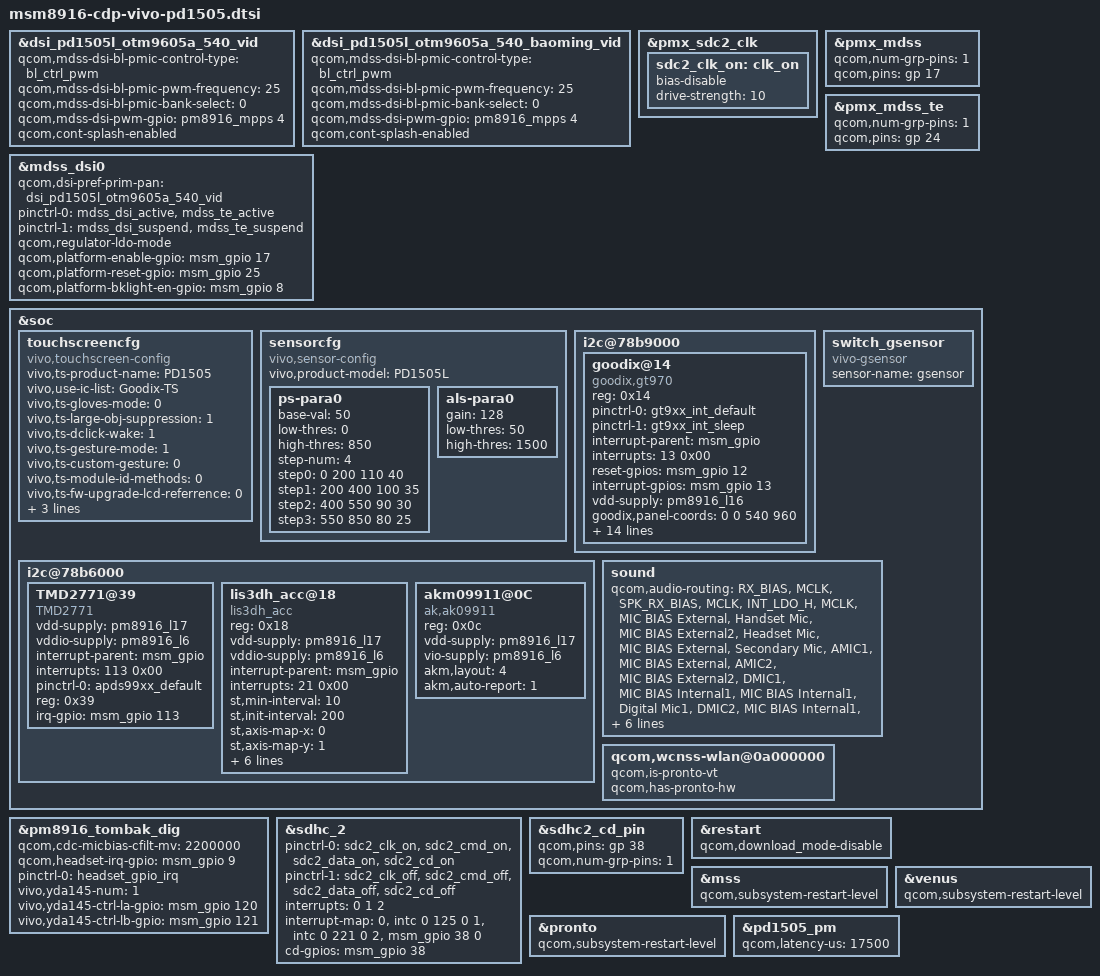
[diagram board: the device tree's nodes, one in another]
/* Copyright (c) 2014-2015, The Linux Foundation. All rights reserved.
 *
 * This program is free software; you can redistribute it and/or modify
 * it under the terms of the GNU General Public License version 2 and
 * only version 2 as published by the Free Software Foundation.
 *
 * This program is distributed in the hope that it will be useful,
 * but WITHOUT ANY WARRANTY; without even the implied warranty of
 * MERCHANTABILITY or FITNESS FOR A PARTICULAR PURPOSE.  See the
 * GNU General Public License for more details.
 */
 
#include "dsi-panel-pd1505l-otm9605a-540p-video.dtsi"
#include "dsi-panel-pd1505l-otm9605a-540p-video-baoming.dtsi"
#include "msm8916-camera-sensor-cdp-vivo-pd1505.dtsi"

 &dsi_pd1505l_otm9605a_540_vid {
	qcom,mdss-dsi-bl-pmic-control-type = "bl_ctrl_pwm";
	qcom,mdss-dsi-bl-pmic-pwm-frequency = <25>;
	qcom,mdss-dsi-bl-pmic-bank-select = <0>;
	qcom,mdss-dsi-pwm-gpio = <&pm8916_mpps 4 0>;
	qcom,cont-splash-enabled;
};

&dsi_pd1505l_otm9605a_540_baoming_vid {
	qcom,mdss-dsi-bl-pmic-control-type = "bl_ctrl_pwm";
	qcom,mdss-dsi-bl-pmic-pwm-frequency = <25>;
	qcom,mdss-dsi-bl-pmic-bank-select = <0>;
	qcom,mdss-dsi-pwm-gpio = <&pm8916_mpps 4 0>;
	qcom,cont-splash-enabled;
};


&pmx_sdc2_clk {
    sdc2_clk_on: clk_on {
        bias-disable; /* NO pull */
        drive-strength = <10>; /* 10 MA： 16 MA is too high for PD1505L */
    };
};

&pmx_mdss {
	qcom,num-grp-pins = <1>;
	qcom,pins = <&gp 17>;
};

&pmx_mdss_te {
	qcom,num-grp-pins = <1>;
	qcom,pins = <&gp 24>;
};
&mdss_dsi0 {
	qcom,dsi-pref-prim-pan = <&dsi_pd1505l_otm9605a_540_vid>;
	pinctrl-names = "mdss_default", "mdss_sleep";
	pinctrl-0 = <&mdss_dsi_active &mdss_te_active>;
	pinctrl-1 = <&mdss_dsi_suspend &mdss_te_suspend>;
	qcom,regulator-ldo-mode;
	qcom,platform-enable-gpio = <&msm_gpio 17 0>;
	qcom,platform-reset-gpio = <&msm_gpio 25 0>;
	qcom,platform-bklight-en-gpio = <&msm_gpio 8 0>;
}; 

&soc {

	touchscreencfg { /* vivo ts configure */
	   compatible = "vivo,touchscreen-config";
	   vivo,ts-product-name="PD1505";
	   vivo,use-ic-list="Goodix-TS";
	   
	   /*----- function set BEG ---- */
	   vivo,ts-gloves-mode=<0>;
	   vivo,ts-large-obj-suppression=<1>;
	   vivo,ts-dclick-wake=<1>;
	   vivo,ts-gesture-mode=<1>; /*1=sold in native,2=sold in abroad,3...etc=for custom extensive*/
	   vivo,ts-custom-gesture=<0>;
	   vivo,ts-module-id-methods=<0>;/*0=by IC id,1=gpio,2=by LCD ID 3=...etc=for custom extensive*/
	   vivo,ts-fw-upgrade-lcd-referrence=<0>;
	   vivo,ts-anti-esd=<1>;
	   vivo,ts-charger-conn-judge=<1>;
	   vivo,ts-module-smt-mode=<1>; /* 0=COB,1=COF */
	   /*----- function set END ---- */

	};
	
	sensorcfg {
		compatible = "vivo,sensor-config";
		vivo,product-model = "PD1505L";
		ps-para0 {
			base-val = <50>;
			low-thres = <0>;
			high-thres = <850>;
			step-num = <4>;
			step0 = <  0 200 110 40>;
			step1 = <200 400 100 35>;
			step2 = <400 550 90 30>;
			step3 = <550 850 80 25>;
		};
		
		als-para0 {
			gain = <128>;
			low-thres = <50>;
			high-thres = <1500>;
		};
	};

	
	i2c@78b9000 { /* BLSP1 QUP5 */
		goodix@14 { //gt970L
			compatible = "goodix,gt970";
			reg = <0x14>;
			/* pins used by touchscreen */
			pinctrl-names = "gt9xx_int_default","gt9xx_int_suspend";
            		pinctrl-0 = <&gt9xx_int_default>;
            		pinctrl-1 = <&gt9xx_int_sleep>;
			interrupt-parent = <&msm_gpio>;
			interrupts = <13 0x00>;
			reset-gpios = <&msm_gpio 12 0x00>;
			interrupt-gpios = <&msm_gpio 13 0x00>;
            		//vcc_i2c-supply = <&pm8916_l6>;
            		vdd-supply = <&pm8916_l16>;/* <&tp_power>;*/
			goodix,panel-coords = <0 0 540 960>;
			goodix,display-coords = <0 0 540 960>;
			goodix,button-map= <158 102 139>;
			goodix,family-id = <0x0>;
           		goodix,i2c-pull-up;
			goodix,cfg-data0 =    //lansi PD1505F_EX项目
			[
				 48 1C 02 09 04 0A 34 10 01 08 
				 32 08 55 32 33 35 00 00 37 13 
				 00 22 00 14 14 28 14 8B 2B 0C 
				 37 39 D3 07 D3 07 00 9A 33 11 
				 00 00 00 00 00 03 00 08 0A A0 
				 22 1E 5F 94 D0 02 BC 19 00 04 
				 C6 21 00 A0 2A 1E 84 35 00 6D 
				 43 00 5B 55 00 5B 00 00 00 00 
				 00 00 00 00 00 00 00 00 00 00 
				 00 00 00 00 F7 01 00 00 00 00 
				 00 00 00 00 00 0F 50 00 00 00 
				 00 1E 0E 10 12 18 16 14 06 04 
				 02 08 0A 0C FF FF 00 00 00 00 
				 00 00 00 00 08 00 78 04 FE 00 
				 50 41 00 02 04 06 08 0A 0C 0F 
				 10 12 13 16 18 1C 1D 1E 1F 20 
				 21 22 24 26 FF FF FF FF 00 00 
				 00 00 00 00 00 00 00 00 00 00 
				 00 00 00 00 C6 01
			];                                         
			
			goodix,cfg-data2 =    //lansi
			[
				 48 1C 02 09 04 0A 34 10 01 08 
				 32 08 55 32 33 35 00 00 37 13 
				 00 22 00 14 14 28 14 8B 2B 0C 
				 37 39 D3 07 D3 07 00 9A 33 11 
				 00 00 00 00 00 03 00 08 0A A0 
				 22 1E 5F 94 D0 02 BC 19 00 04 
				 C6 21 00 A0 2A 1E 84 35 00 6D 
				 43 00 5B 55 00 5B 00 00 00 00 
				 00 00 00 00 00 00 00 00 00 00 
				 00 00 00 00 F7 01 00 00 00 00 
				 00 00 00 00 00 0F 50 00 00 00 
				 00 1E 0E 10 12 18 16 14 06 04 
				 02 08 0A 0C FF FF 00 00 00 00 
				 00 00 00 00 08 00 78 04 FE 00 
				 50 41 00 02 04 06 08 0A 0C 0F 
				 10 12 13 16 18 1C 1D 1E 1F 20 
				 21 22 24 26 FF FF FF FF 00 00 
				 00 00 00 00 00 00 00 00 00 00 
				 00 00 00 00 C6 01
			];              
			
			goodix,cfg-data3 =    //lansi
			[
				 4A 1C 02 09 04 0A 34 10 01 08 
				 32 08 55 32 33 35 00 00 37 13 
				 00 22 00 14 14 28 14 8B 2B 0C 
				 37 39 D3 07 D3 07 00 9A 33 11 
				 00 00 00 00 00 03 00 08 0A A0 
				 22 1E 5F 94 D0 02 BC 19 00 04 
				 C6 21 00 A0 2A 1E 84 35 00 6D 
				 43 00 5B 55 00 5B 00 00 00 00 
				 00 00 00 00 00 00 00 00 00 00 
				 00 00 00 00 F7 01 00 00 00 00 
				 00 00 00 00 00 0F 50 00 00 00 
				 00 1E 0E 10 12 18 16 14 06 04 
				 02 08 0A 0C FF FF 00 00 00 00 
				 00 00 00 00 08 00 78 04 FE 00 
				 40 41 00 02 04 06 08 0A 0C 0F 
				 10 12 13 16 18 1C 1D 1E 1F 20 
				 21 22 24 26 FF FF FF FF 00 00 
				 00 00 00 00 00 00 00 00 00 00 
				 00 00 00 00 D4 01
			];                                   
				
			ts-suspend-resume=<0>;
			ts-fixed-key-type=<1>; /*0=0d,1=2d */
			
			/*--virtualkeys: EV_KEY:KEY_MENU:cx:cy:w:h:EV_KEY:KEY_HOMEPAGE:cx:cy:w:h:EV_KEY:KEY_BACK:cx:cy:w:h--*/
			ts-virt-key="0x01:139:85:1020:140:100:0x01:251:170:1020:95:100:0x01:172:263:1020:140:100:0x01:251:355:1020:100:100:0x01:158:450:1020:140:100";
		};
	
	};
    switch_gsensor {
		  compatible = "vivo-gsensor";
		  sensor-name = "gsensor";
		/*  sensor,gpio-irq = <&msm_gpio 21 0x00>;  */
	  };
	i2c@78b6000 { /* BLSP1 QUP2 */ 	
		TMD2771@39 {
			compatible = "TMD2771";
			vdd-supply = <&pm8916_l17>;
			vddio-supply = <&pm8916_l6>;
			interrupt-parent = <&msm_gpio>;
			interrupts = <113 0x00>;
			pinctrl-names = "default";
			pinctrl-0 = <&apds99xx_default>;
			reg = <0x39>;
			irq-gpio = <&msm_gpio 113 0x00>;
		};
		lis3dh_acc@18 {
			compatible = "lis3dh_acc";
			reg = <0x18>;
			vdd-supply = <&pm8916_l17>;
			vddio-supply = <&pm8916_l6>;
			interrupt-parent = <&msm_gpio>;
			interrupts = <21 0x00>;
			st,min-interval = <10>;
			st,init-interval = <200>;
			st,axis-map-x = <0>;
			st,axis-map-y = <1>;
			st,axis-map-z = <2>;
			st,g-range = <2>;
			st,negate-x = <1>;
			st,negate-y = <1>;
			st,negate-z = <0>;
            sensor,gpio-irq = <&msm_gpio 21 0x00>;			
		};
		/*akm8963@0D {
			compatible = "akm,akm8963";
			reg = <0x0D>;
			ak,layout =<4>;
			ak,auto-report=<1>;
			vdd-supply = <&pm8916_l17>;
			vio-supply = <&pm8916_l6>;
			iic-address=<0x0C>;
		};*/
	    akm09911@0C{
		    compatible = "ak,ak09911";
		    reg = <0x0c>;
		    vdd-supply = <&pm8916_l17>;
		    vio-supply = <&pm8916_l6>;
		    akm,layout = <4>;
		    akm,auto-report=<1>;
	    };
		/*yas533@2E {
			compatible = "yas533_mag";
			reg = <0x2E>;
			ak,layout =<0>;
			vdd-supply = <&pm8916_l17>;
			vio-supply = <&pm8916_l6>;
		};*/
	};
	sound {
		qcom,audio-routing =
			"RX_BIAS", "MCLK",
			"SPK_RX_BIAS", "MCLK",
			"INT_LDO_H", "MCLK",
			"MIC BIAS External", "Handset Mic",
			"MIC BIAS External2", "Headset Mic",
			"MIC BIAS External", "Secondary Mic",
			"AMIC1", "MIC BIAS External",
			"AMIC2", "MIC BIAS External2",		
			"DMIC1", "MIC BIAS Internal1",
			"MIC BIAS Internal1", "Digital Mic1",
			"DMIC2", "MIC BIAS Internal1",
			"MIC BIAS Internal1", "Digital Mic2",
			"KTV Handset Mic In", "MIC BIAS External",
			"KTV Headset Mic In", "MIC BIAS External2";
		vivo,fm-support;
		vivo,fm-pcm-hp = <5>;
		vivo,fm-pcm-spk = <5>;
	};

	qcom,wcnss-wlan@0a000000 {
		/* qcom,has-autodetect-xo; */ 
		qcom,is-pronto-vt;   
		qcom,has-pronto-hw;  
	};	

};



&pm8916_tombak_dig{
		qcom,cdc-micbias-cfilt-mv = <2200000>;
		qcom,headset-irq-gpio = <&msm_gpio 9 0>;
		pinctrl-names = "headset_gpio_irq";
		pinctrl-0 =  <&headset_gpio_irq>;
		vivo,yda145-num=<1>;
		vivo,yda145-ctrl-la-gpio=<&msm_gpio 120 0>;
		vivo,yda145-ctrl-lb-gpio=<&msm_gpio 121 0>;
};

 
&sdhc_2 {
	    pinctrl-names = "active", "sleep";
		pinctrl-0 = <&sdc2_clk_on &sdc2_cmd_on &sdc2_data_on &sdc2_cd_on>;
		pinctrl-1 = <&sdc2_clk_off &sdc2_cmd_off &sdc2_data_off &sdc2_cd_off>;
};
&sdhc_2 {
    interrupts = <0 1 2>;
    interrupt-map = <0 &intc 0 125 0
			1 &intc 0 221 0
			2 &msm_gpio 38 0>;
    cd-gpios = <&msm_gpio 38 0x0>;
};

&sdhc2_cd_pin {
			qcom,pins = <&gp 38>;
			qcom,num-grp-pins = <1>;
};

&restart {
	qcom,download_mode-disable;
};
&mss {
	qcom,subsystem-restart-level;
};
&venus {
	qcom,subsystem-restart-level;
};
&pronto {
	qcom,subsystem-restart-level;
};

&pd1505_pm{
	qcom,latency-us = <17500>;
};


